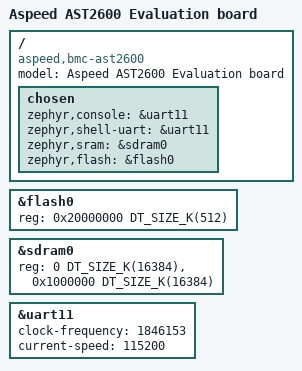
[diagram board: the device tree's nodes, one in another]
/*
 * Copyright (c) 2021 ASPEED Technology Inc.
 *
 * SPDX-License-Identifier: Apache-2.0
 */

/dts-v1/;
#include <aspeed/ast26xx.dtsi>

/ {
	model = "Aspeed AST2600 Evaluation board";
	compatible = "aspeed,bmc-ast2600", "aspeed,ast2600";

	chosen {
		zephyr,console = &uart11;
		zephyr,shell-uart = &uart11;
		zephyr,sram = &sdram0;
		zephyr,flash = &flash0;
	};
};

&flash0 {
	reg = <0x20000000 DT_SIZE_K(512)>;
};

&sdram0 {
	reg = <0 DT_SIZE_K(16384)>, <0x1000000 DT_SIZE_K(16384)>;
};

&uart11 {
	clock-frequency = <1846153>;
	current-speed = <115200>;
	status = "okay";
};
